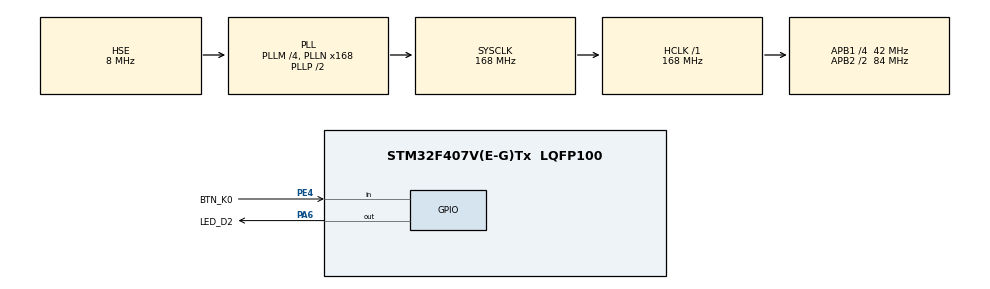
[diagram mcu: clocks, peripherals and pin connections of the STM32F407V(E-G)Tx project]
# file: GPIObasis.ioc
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Mcu.Family=STM32F4
Mcu.Name=STM32F407V(E-G)Tx
Mcu.Package=LQFP100
NVIC.PriorityGroup=NVIC_PRIORITYGROUP_4
PA13.Mode=Serial_Wire
PA13.Signal=SYS_JTMS-SWDIO
PA14.Mode=Serial_Wire
PA14.Signal=SYS_JTCK-SWCLK
PA6.GPIO_Label=LED_D2
PA6.PinState=GPIO_PIN_SET
PA6.Signal=GPIO_Output
PE4.GPIO_Label=BTN_K0
PE4.GPIO_PuPd=GPIO_PULLUP
PE4.Signal=GPIO_Input
PH0-OSC_IN.Mode=HSE-External-Oscillator
PH0-OSC_IN.Signal=RCC_OSC_IN
PH1-OSC_OUT.Mode=HSE-External-Oscillator
PH1-OSC_OUT.Signal=RCC_OSC_OUT
ProjectManager.HeapSize=0x200
ProjectManager.StackSize=0x400
ProjectManager.TargetToolchain=STM32CubeIDE
RCC.48MHZClocksFreq_Value=84000000
RCC.AHBFreq_Value=168000000
RCC.APB1CLKDivider=RCC_HCLK_DIV4
RCC.APB1Freq_Value=42000000
RCC.APB1TimFreq_Value=84000000
RCC.APB2CLKDivider=RCC_HCLK_DIV2
RCC.APB2Freq_Value=84000000
RCC.APB2TimFreq_Value=168000000
RCC.CortexFreq_Value=168000000
RCC.HCLKFreq_Value=168000000
RCC.HSE_VALUE=8000000
RCC.HSI_VALUE=16000000
RCC.LSE_VALUE=32768
RCC.PLLM=4
RCC.PLLN=168
RCC.PLLSourceVirtual=RCC_PLLSOURCE_HSE
RCC.SYSCLKFreq_VALUE=168000000
RCC.SYSCLKSource=RCC_SYSCLKSOURCE_PLLCLK
RCC.VCOOutputFreq_Value=336000000
board=custom

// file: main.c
/* USER CODE BEGIN Header */
/**
  ******************************************************************************
  * @file           : main.c
  * @brief          : Main program body
  ******************************************************************************
  * @attention
  *
  * Copyright (c) 2024 STMicroelectronics.
  * All rights reserved.
  *
  * This software is licensed under terms that can be found in the LICENSE file
  * in the root directory of this software component.
  * If no LICENSE file comes with this software, it is provided AS-IS.
  *
  ******************************************************************************
  */
/* USER CODE END Header */
#include "main.h"

void SystemClock_Config(void);
static void MX_GPIO_Init(void);

/* USER CODE BEGIN 0 */
void Delay_us(volatile uint32_t delay){
	//careful timer 4 is only 16 bits
	TIM5->PSC = SystemCoreClock/1000000-1;//set timer prescaler register
	TIM5->ARR = delay; // set timer auto-reload register
	TIM5->EGR |= TIM_EGR_UG; //SET UG BIT IN EGR REGISTER TO UPDATE UPCOUNTING MODE
	TIM5->CR1 |= TIM_CR1_CEN| TIM_CR1_OPM;// SET ONE PULSE MODE AND ENAIBLE THE COUNTER
	while((TIM5->CR1)&(TIM_CR1_CEN!=0));// CHECK COUNTER ENAIBLE BIT - IT CLEARS AUTOMATICALY IN ONE PULSE MODE WHEN AN UPDATE EVENT OCURS
}
/* USER CODE END 0 */

int main(void)
{
  /* USER CODE BEGIN 1 */
	uint8_t btn_k0;
  /* USER CODE END 1 */

  /* MCU Configuration--------------------------------------------------------*/

  /* Reset of all peripherals, Initializes the Flash interface and the Systick. */
  HAL_Init();

  /* Configure the system clock */
  SystemClock_Config();

  /* Initialize all configured peripherals */
  MX_GPIO_Init();
  /* USER CODE BEGIN 2 */
  SET_BIT(RCC->APB1ENR, RCC_APB1ENR_TIM5EN); // delay timer initialization
  /* USER CODE END 2 */

  /* Infinite loop */
  while (1)
  {

    /* USER CODE BEGIN 3 */
	  btn_k0 = HAL_GPIO_ReadPin(BTN_K0_GPIO_Port, BTN_K0_Pin); //read pin 4 status
	  if (btn_k0 == 0 )// if switch k0 pressed
	  {
		  HAL_GPIO_WritePin(LED_D2_GPIO_Port, LED_D2_Pin, GPIO_PIN_RESET); // RESET PIN 6 (led on)
		  Delay_us(2000000);// 2 seconds delay
		  HAL_GPIO_WritePin(LED_D2_GPIO_Port, LED_D2_Pin, GPIO_PIN_SET);// Set pin 6 (led off)
	  }
  }
  /* USER CODE END 3 */
}

void SystemClock_Config(void)
{
  RCC_OscInitTypeDef RCC_OscInitStruct = {0};
  RCC_ClkInitTypeDef RCC_ClkInitStruct = {0};

  /** Configure the main internal regulator output voltage
  */
  __HAL_RCC_PWR_CLK_ENABLE();
  __HAL_PWR_VOLTAGESCALING_CONFIG(PWR_REGULATOR_VOLTAGE_SCALE1);

  /** Initializes the RCC Oscillators according to the specified parameters
  * in the RCC_OscInitTypeDef structure.
  */
  RCC_OscInitStruct.OscillatorType = RCC_OSCILLATORTYPE_HSE;
  RCC_OscInitStruct.HSEState = RCC_HSE_ON;
  RCC_OscInitStruct.PLL.PLLState = RCC_PLL_ON;
  RCC_OscInitStruct.PLL.PLLSource = RCC_PLLSOURCE_HSE;
  RCC_OscInitStruct.PLL.PLLM = 4;
  RCC_OscInitStruct.PLL.PLLN = 168;
  RCC_OscInitStruct.PLL.PLLP = RCC_PLLP_DIV2;
  RCC_OscInitStruct.PLL.PLLQ = 4;
  if (HAL_RCC_OscConfig(&RCC_OscInitStruct) != HAL_OK)
  {
    Error_Handler();
  }

  /** Initializes the CPU, AHB and APB buses clocks
  */
  RCC_ClkInitStruct.ClockType = RCC_CLOCKTYPE_HCLK|RCC_CLOCKTYPE_SYSCLK
                              |RCC_CLOCKTYPE_PCLK1|RCC_CLOCKTYPE_PCLK2;
  RCC_ClkInitStruct.SYSCLKSource = RCC_SYSCLKSOURCE_PLLCLK;
  RCC_ClkInitStruct.AHBCLKDivider = RCC_SYSCLK_DIV1;
  RCC_ClkInitStruct.APB1CLKDivider = RCC_HCLK_DIV4;
  RCC_ClkInitStruct.APB2CLKDivider = RCC_HCLK_DIV2;

  if (HAL_RCC_ClockConfig(&RCC_ClkInitStruct, FLASH_LATENCY_5) != HAL_OK)
  {
    Error_Handler();
  }
}

static void MX_GPIO_Init(void)
{
  GPIO_InitTypeDef GPIO_InitStruct = {0};

  /* GPIO Ports Clock Enable */
  __HAL_RCC_GPIOE_CLK_ENABLE();
  __HAL_RCC_GPIOH_CLK_ENABLE();
  __HAL_RCC_GPIOA_CLK_ENABLE();

  /*Configure GPIO pin Output Level */
  HAL_GPIO_WritePin(LED_D2_GPIO_Port, LED_D2_Pin, GPIO_PIN_SET);

  /*Configure GPIO pin : BTN_K0_Pin */
  GPIO_InitStruct.Pin = BTN_K0_Pin;
  GPIO_InitStruct.Mode = GPIO_MODE_INPUT;
  GPIO_InitStruct.Pull = GPIO_PULLUP;
  HAL_GPIO_Init(BTN_K0_GPIO_Port, &GPIO_InitStruct);

  /*Configure GPIO pin : LED_D2_Pin */
  GPIO_InitStruct.Pin = LED_D2_Pin;
  GPIO_InitStruct.Mode = GPIO_MODE_OUTPUT_PP;
  GPIO_InitStruct.Pull = GPIO_NOPULL;
  GPIO_InitStruct.Speed = GPIO_SPEED_FREQ_LOW;
  HAL_GPIO_Init(LED_D2_GPIO_Port, &GPIO_InitStruct);

}

void Error_Handler(void)
{
  __disable_irq();
  while (1)
  {
  }
}
